# ESP32-C2 register map
Vendor: ESPRESSIF SYSTEMS (SHANGHAI) CO., LTD.; Series: ESP32 C-Series; File version: 11
CPU: RV32IMC r0p0, little endian, no MPU, no FPU, 0 interrupt priority bits
Address unit: 32 bits
Registers are 32-bit, read-write, reset 0x0 unless marked. A register's access mark holds for its fields unless they carry their own. Offsets are from the block's base; [hi:lo] are bit positions; {n}, {i} and the like mark numbered series.

## I2C_ANA_MST — I2C_ANA_MST Peripheral
Base 0x6004E840
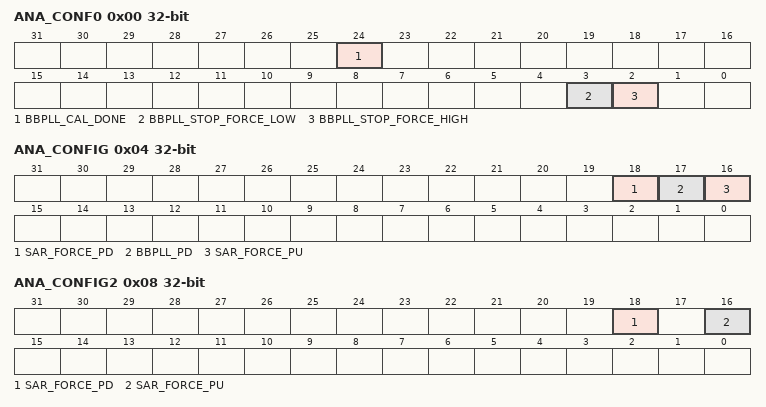
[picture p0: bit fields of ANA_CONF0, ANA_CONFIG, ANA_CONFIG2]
0x00 ANA_CONF0
  [24] BBPLL_CAL_DONE — ?
  [3] BBPLL_STOP_FORCE_LOW — ?
  [2] BBPLL_STOP_FORCE_HIGH — ?
0x04 ANA_CONFIG
  [18] SAR_FORCE_PD — ?
  [17] BBPLL_PD — Clear to enable BBPLL
  [16] SAR_FORCE_PU — ?
0x08 ANA_CONFIG2
  [18] SAR_FORCE_PD — ?
  [16] SAR_FORCE_PU — ?

## RNG — Hardware Random Number Generator
Base 0x60026000
0xB0 DATA ro — Random number data

## SENSITIVE — SENSITIVE Peripheral
Base 0x600C1000
0x00 ROM_TABLE_LOCK — register description
  [0] ROM_TABLE_LOCK — Need add description
0x04 ROM_TABLE — register description
  [31:0] ROM_TABLE — Need add description
0x08 APB_PERIPHERAL_ACCESS_0 — register description
  [0] APB_PERIPHERAL_ACCESS_LOCK — Need add description
0x0C APB_PERIPHERAL_ACCESS_1 reset 0x1 — register description
  [0] APB_PERIPHERAL_ACCESS_SPLIT_BURST — Need add description
0x10 INTERNAL_SRAM_USAGE_0 — register description
  [0] INTERNAL_SRAM_USAGE_LOCK — Need add description
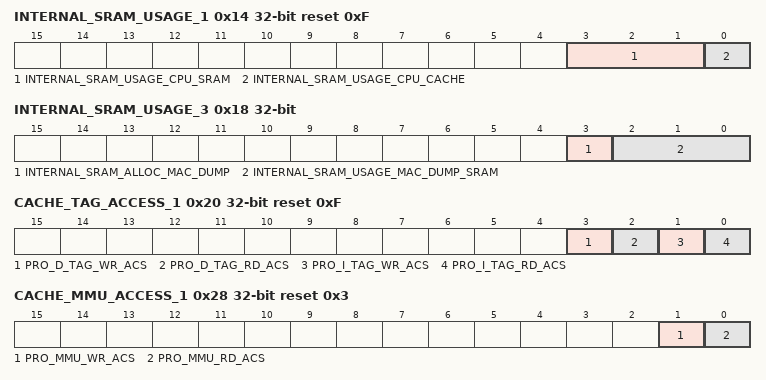
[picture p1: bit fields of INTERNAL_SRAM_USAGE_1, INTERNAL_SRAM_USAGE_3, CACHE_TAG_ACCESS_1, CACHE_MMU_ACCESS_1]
0x14 INTERNAL_SRAM_USAGE_1 reset 0xF — register description
  [3:1] INTERNAL_SRAM_USAGE_CPU_SRAM — Need add description
  [0] INTERNAL_SRAM_USAGE_CPU_CACHE — Need add description
0x18 INTERNAL_SRAM_USAGE_3 — register description
  [3] INTERNAL_SRAM_ALLOC_MAC_DUMP — Need add description
  [2:0] INTERNAL_SRAM_USAGE_MAC_DUMP_SRAM — Need add description
0x1C CACHE_TAG_ACCESS_0 — register description
  [0] CACHE_TAG_ACCESS_LOCK — Need add description
0x20 CACHE_TAG_ACCESS_1 reset 0xF — register description
  [3] PRO_D_TAG_WR_ACS — Need add description
  [2] PRO_D_TAG_RD_ACS — Need add description
  [1] PRO_I_TAG_WR_ACS — Need add description
  [0] PRO_I_TAG_RD_ACS — Need add description
0x24 CACHE_MMU_ACCESS_0 — register description
  [0] CACHE_MMU_ACCESS_LOCK — Need add description
0x28 CACHE_MMU_ACCESS_1 reset 0x3 — register description
  [1] PRO_MMU_WR_ACS — Need add description
  [0] PRO_MMU_RD_ACS — Need add description
0x2C PIF_ACCESS_MONITOR_0 — register description
  [0] PIF_ACCESS_MONITOR_LOCK — Need add description
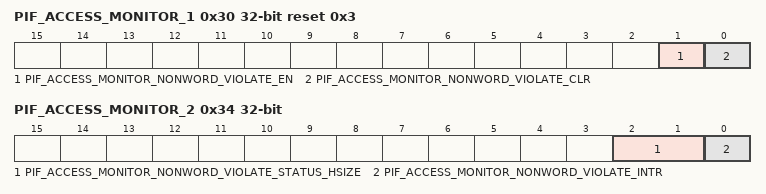
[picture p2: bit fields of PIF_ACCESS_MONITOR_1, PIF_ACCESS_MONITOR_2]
0x30 PIF_ACCESS_MONITOR_1 reset 0x3 — register description
  [1] PIF_ACCESS_MONITOR_NONWORD_VIOLATE_EN — Need add description
  [0] PIF_ACCESS_MONITOR_NONWORD_VIOLATE_CLR — Need add description
0x34 PIF_ACCESS_MONITOR_2 ro — register description
  [2:1] PIF_ACCESS_MONITOR_NONWORD_VIOLATE_STATUS_HSIZE — Need add description
  [0] PIF_ACCESS_MONITOR_NONWORD_VIOLATE_INTR — Need add description
0x38 PIF_ACCESS_MONITOR_3 ro — register description
  [31:0] PIF_ACCESS_MONITOR_NONWORD_VIOLATE_STATUS_HADDR — Need add description
0x3C XTS_AES_KEY_UPDATE — register description
  [0] XTS_AES_KEY_UPDATE — Set this bit to update xts_aes key
0x40 CLOCK_GATE reset 0x1 — register description
  [0] CLK_EN — Need add description
0xFFC SENSITIVE_REG_DATE — register description

## SHA — SHA (Secure Hash Algorithm) Accelerator
Base 0x6003B000
0x00 MODE — Initial configuration register.
  [2:0] MODE — Sha mode.
0x04 T_STRING — SHA 512/t configuration register 0.
  [31:0] T_STRING — Sha t_string (used if and only if mode == SHA_512/t).
0x08 T_LENGTH — SHA 512/t configuration register 1.
  [5:0] T_LENGTH — Sha t_length (used if and only if mode == SHA_512/t).
0x0C DMA_BLOCK_NUM — DMA configuration register 0.
  [5:0] DMA_BLOCK_NUM — Dma-sha block number.
0x10 START wo — Typical SHA configuration register 0.
  [0] START — Write 1 to start Typical SHA calculation.
0x14 CONTINUE wo — Typical SHA configuration register 1.
  [0] CONTINUE — Write 1 to continue Typical SHA calculation.
0x18 BUSY ro
  [0] STATE — Sha busy state. 1'b0: idle. 1'b1: busy.
0x1C DMA_START wo — DMA configuration register 1.
  [0] DMA_START — Start dma-sha.
0x20 DMA_CONTINUE wo — DMA configuration register 2.
  [0] DMA_CONTINUE — Continue dma-sha.
0x24 CLEAR_IRQ wo — Interrupt clear register.
  [0] CLEAR_INTERRUPT — Clear sha interrupt.
0x28 IRQ_ENA — Interrupt enable register.
  [0] INTERRUPT_ENA — Sha interrupt enable register. 1'b0: disable(default). 1'b1: enable.
0x2C DATE
{0x40+4i} H_MEM[{i}] (i=0..7) access not given — Sha H memory which contains intermediate hash or finial hash.
{0x80+4i} M_MEM[{i}] (i=0..15) access not given — Sha M memory which contains message.
